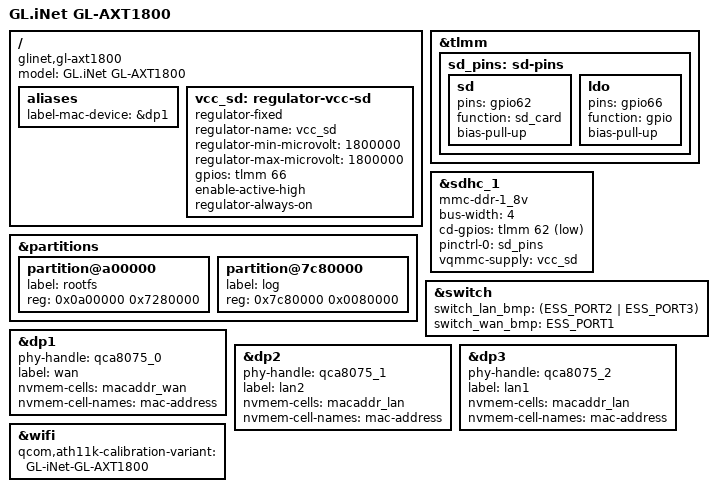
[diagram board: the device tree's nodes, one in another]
// SPDX-License-Identifier: GPL-2.0-or-later OR MIT

/dts-v1/;

#include "ipq6018-glinet.dtsi"

/ {
	model = "GL.iNet GL-AXT1800";
	compatible = "glinet,gl-axt1800", "qcom,ipq6018";

	aliases {
		label-mac-device = &dp1;
	};

	vcc_sd: regulator-vcc-sd {
		compatible = "regulator-fixed";
		regulator-name = "vcc_sd";
		regulator-min-microvolt = <1800000>;
		regulator-max-microvolt = <1800000>;
		gpios = <&tlmm 66 GPIO_ACTIVE_HIGH>;
		enable-active-high;
		regulator-always-on;
	};

	/*
	 * OpenMANET's 6.6 kernel base lacks the IPQ6018 PWM controller node.
	 * Upstream main's pwm-fan + thermal-zones omitted here — fan will run
	 * at unmanaged speed. Backporting the PWM patch from upstream main's
	 * patches-6.12/ is a follow-up.
	 */
};

&tlmm {
	sd_pins: sd-pins {
		sd {
			pins = "gpio62";
			function = "sd_card";
			bias-pull-up;
		};
		ldo {
			pins = "gpio66";
			function = "gpio";
			bias-pull-up;
		};
	};
};

&partitions {
	partition@a00000 {
		label = "rootfs";
		reg = <0x0a00000 0x7280000>;
	};

	partition@7c80000 {
		label = "log";
		reg = <0x7c80000 0x0080000>;
	};
};

&sdhc_1 {
	mmc-ddr-1_8v;
	bus-width = <4>;
	cd-gpios = <&tlmm 62 GPIO_ACTIVE_LOW>;
	pinctrl-0 = <&sd_pins>;
	pinctrl-names = "default";
	vqmmc-supply = <&vcc_sd>;
	status = "okay";
};

&switch {
	switch_lan_bmp = <(ESS_PORT2 | ESS_PORT3)>;
	switch_wan_bmp = <ESS_PORT1>;
};

&dp1 {
	status = "okay";
	phy-handle = <&qca8075_0>;
	label = "wan";
	nvmem-cells = <&macaddr_wan>;
	nvmem-cell-names = "mac-address";
};

&dp2 {
	status = "okay";
	phy-handle = <&qca8075_1>;
	label = "lan2";
	nvmem-cells = <&macaddr_lan>;
	nvmem-cell-names = "mac-address";
};

&dp3 {
	status = "okay";
	phy-handle = <&qca8075_2>;
	label = "lan1";
	nvmem-cells = <&macaddr_lan>;
	nvmem-cell-names = "mac-address";
};

&wifi {
	qcom,ath11k-calibration-variant = "GL-iNet-GL-AXT1800";
};
